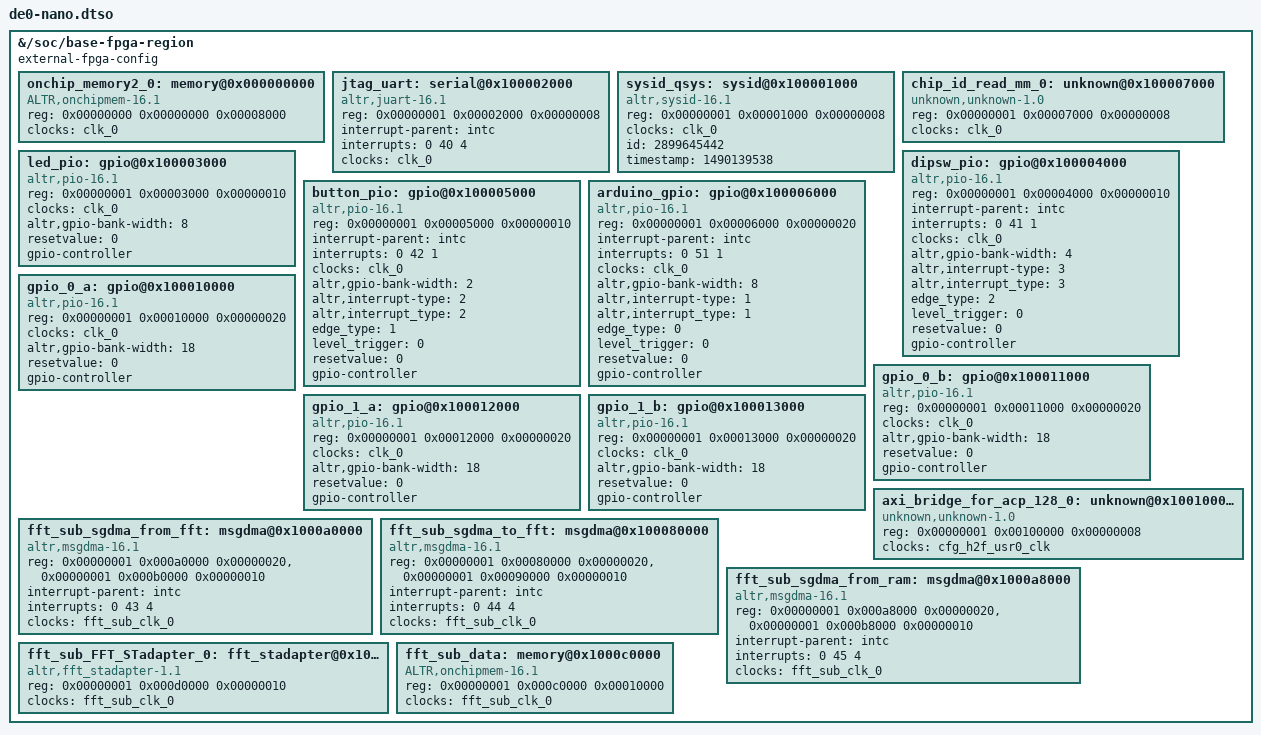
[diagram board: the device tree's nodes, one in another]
/*
 * This devicetree is generated by sopc2dts version  on Tue Mar 21 16:55:32 PDT 2017
 * Sopc2dts is written by Walter Goossens <waltergoossens@home.nl>
 * in cooperation with the nios2 community <nios2-dev@lists.rocketboards.org>
 */
/dts-v1/;
/plugin/;
/include/ "de0-nano.dtsi"

/ {

	fragment@0 {
		target-path = "/soc/base-fpga-region";

		__overlay__ {
			external-fpga-config;
			#address-cells = <2>;
			#size-cells = <1>;
			ranges = <0x00000000 0x00000000 0xc0000000 0x20000000>,
				<0x00000001 0x00000000 0xff200000 0x00200000>;

			onchip_memory2_0: memory@0x000000000 {
				device_type = "memory";
				compatible = "ALTR,onchipmem-16.1";
				reg = <0x00000000 0x00000000 0x00008000>;
				clocks = <&clk_0>;
			}; //end memory@0x000000000 (onchip_memory2_0)

			jtag_uart: serial@0x100002000 {
				compatible = "altr,juart-16.1", "altr,juart-1.0";
				reg = <0x00000001 0x00002000 0x00000008>;
				interrupt-parent = <&intc>;
				interrupts = <0 40 4>;
				clocks = <&clk_0>;
			}; //end serial@0x100002000 (jtag_uart)

			sysid_qsys: sysid@0x100001000 {
				compatible = "altr,sysid-16.1", "altr,sysid-1.0";
				reg = <0x00000001 0x00001000 0x00000008>;
				clocks = <&clk_0>;
				id = <2899645442>;	/* embeddedsw.dts.params.id type NUMBER */
				timestamp = <1490139538>;	/* embeddedsw.dts.params.timestamp type NUMBER */
			}; //end sysid@0x100001000 (sysid_qsys)

			chip_id_read_mm_0: unknown@0x100007000 {
				compatible = "unknown,unknown-1.0";
				reg = <0x00000001 0x00007000 0x00000008>;
				clocks = <&clk_0>;
			}; //end unknown@0x100007000 (chip_id_read_mm_0)

			led_pio: gpio@0x100003000 {
				compatible = "altr,pio-16.1", "altr,pio-1.0";
				reg = <0x00000001 0x00003000 0x00000010>;
				clocks = <&clk_0>;
				altr,gpio-bank-width = <8>;	/* embeddedsw.dts.params.altr,gpio-bank-width type NUMBER */
				resetvalue = <0>;	/* embeddedsw.dts.params.resetvalue type NUMBER */
				#gpio-cells = <2>;
				gpio-controller;
			}; //end gpio@0x100003000 (led_pio)

			dipsw_pio: gpio@0x100004000 {
				compatible = "altr,pio-16.1", "altr,pio-1.0";
				reg = <0x00000001 0x00004000 0x00000010>;
				interrupt-parent = <&intc>;
				interrupts = <0 41 1>;
				clocks = <&clk_0>;
				altr,gpio-bank-width = <4>;	/* embeddedsw.dts.params.altr,gpio-bank-width type NUMBER */
				altr,interrupt-type = <3>;	/* embeddedsw.dts.params.altr,interrupt-type type NUMBER */
				altr,interrupt_type = <3>;	/* embeddedsw.dts.params.altr,interrupt_type type NUMBER */
				edge_type = <2>;	/* embeddedsw.dts.params.edge_type type NUMBER */
				level_trigger = <0>;	/* embeddedsw.dts.params.level_trigger type NUMBER */
				resetvalue = <0>;	/* embeddedsw.dts.params.resetvalue type NUMBER */
				#gpio-cells = <2>;
				gpio-controller;
			}; //end gpio@0x100004000 (dipsw_pio)

			button_pio: gpio@0x100005000 {
				compatible = "altr,pio-16.1", "altr,pio-1.0";
				reg = <0x00000001 0x00005000 0x00000010>;
				interrupt-parent = <&intc>;
				interrupts = <0 42 1>;
				clocks = <&clk_0>;
				altr,gpio-bank-width = <2>;	/* embeddedsw.dts.params.altr,gpio-bank-width type NUMBER */
				altr,interrupt-type = <2>;	/* embeddedsw.dts.params.altr,interrupt-type type NUMBER */
				altr,interrupt_type = <2>;	/* embeddedsw.dts.params.altr,interrupt_type type NUMBER */
				edge_type = <1>;	/* embeddedsw.dts.params.edge_type type NUMBER */
				level_trigger = <0>;	/* embeddedsw.dts.params.level_trigger type NUMBER */
				resetvalue = <0>;	/* embeddedsw.dts.params.resetvalue type NUMBER */
				#gpio-cells = <2>;
				gpio-controller;
			}; //end gpio@0x100005000 (button_pio)

			arduino_gpio: gpio@0x100006000 {
				compatible = "altr,pio-16.1", "altr,pio-1.0";
				reg = <0x00000001 0x00006000 0x00000020>;
				interrupt-parent = <&intc>;
				interrupts = <0 51 1>;
				clocks = <&clk_0>;
				altr,gpio-bank-width = <8>;	/* embeddedsw.dts.params.altr,gpio-bank-width type NUMBER */
				altr,interrupt-type = <1>;	/* embeddedsw.dts.params.altr,interrupt-type type NUMBER */
				altr,interrupt_type = <1>;	/* embeddedsw.dts.params.altr,interrupt_type type NUMBER */
				edge_type = <0>;	/* embeddedsw.dts.params.edge_type type NUMBER */
				level_trigger = <0>;	/* embeddedsw.dts.params.level_trigger type NUMBER */
				resetvalue = <0>;	/* embeddedsw.dts.params.resetvalue type NUMBER */
				#gpio-cells = <2>;
				gpio-controller;
			}; //end gpio@0x100006000 (arduino_gpio)

			gpio_0_a: gpio@0x100010000 {
				compatible = "altr,pio-16.1", "altr,pio-1.0";
				reg = <0x00000001 0x00010000 0x00000020>;
				clocks = <&clk_0>;
				altr,gpio-bank-width = <18>;	/* embeddedsw.dts.params.altr,gpio-bank-width type NUMBER */
				resetvalue = <0>;	/* embeddedsw.dts.params.resetvalue type NUMBER */
				#gpio-cells = <2>;
				gpio-controller;
			}; //end gpio@0x100010000 (gpio_0_a)

			gpio_0_b: gpio@0x100011000 {
				compatible = "altr,pio-16.1", "altr,pio-1.0";
				reg = <0x00000001 0x00011000 0x00000020>;
				clocks = <&clk_0>;
				altr,gpio-bank-width = <18>;	/* embeddedsw.dts.params.altr,gpio-bank-width type NUMBER */
				resetvalue = <0>;	/* embeddedsw.dts.params.resetvalue type NUMBER */
				#gpio-cells = <2>;
				gpio-controller;
			}; //end gpio@0x100011000 (gpio_0_b)

			gpio_1_a: gpio@0x100012000 {
				compatible = "altr,pio-16.1", "altr,pio-1.0";
				reg = <0x00000001 0x00012000 0x00000020>;
				clocks = <&clk_0>;
				altr,gpio-bank-width = <18>;	/* embeddedsw.dts.params.altr,gpio-bank-width type NUMBER */
				resetvalue = <0>;	/* embeddedsw.dts.params.resetvalue type NUMBER */
				#gpio-cells = <2>;
				gpio-controller;
			}; //end gpio@0x100012000 (gpio_1_a)

			gpio_1_b: gpio@0x100013000 {
				compatible = "altr,pio-16.1", "altr,pio-1.0";
				reg = <0x00000001 0x00013000 0x00000020>;
				clocks = <&clk_0>;
				altr,gpio-bank-width = <18>;	/* embeddedsw.dts.params.altr,gpio-bank-width type NUMBER */
				resetvalue = <0>;	/* embeddedsw.dts.params.resetvalue type NUMBER */
				#gpio-cells = <2>;
				gpio-controller;
			}; //end gpio@0x100013000 (gpio_1_b)

			axi_bridge_for_acp_128_0: unknown@0x100100000 {
				compatible = "unknown,unknown-1.0";
				reg = <0x00000001 0x00100000 0x00000008>;
				clocks = <&cfg_h2f_usr0_clk>;
			}; //end unknown@0x100100000 (axi_bridge_for_acp_128_0)

			fft_sub_sgdma_from_fft: msgdma@0x1000a0000 {
				compatible = "altr,msgdma-16.1", "altr,msgdma-1.0";
				reg = <0x00000001 0x000a0000 0x00000020>,
					<0x00000001 0x000b0000 0x00000010>;
				reg-names = "csr", "descriptor_slave";
				interrupt-parent = <&intc>;
				interrupts = <0 43 4>;
				clocks = <&fft_sub_clk_0>;
			}; //end msgdma@0x1000a0000 (fft_sub_sgdma_from_fft)

			fft_sub_sgdma_to_fft: msgdma@0x100080000 {
				compatible = "altr,msgdma-16.1", "altr,msgdma-1.0";
				reg = <0x00000001 0x00080000 0x00000020>,
					<0x00000001 0x00090000 0x00000010>;
				reg-names = "csr", "descriptor_slave";
				interrupt-parent = <&intc>;
				interrupts = <0 44 4>;
				clocks = <&fft_sub_clk_0>;
			}; //end msgdma@0x100080000 (fft_sub_sgdma_to_fft)

			fft_sub_sgdma_from_ram: msgdma@0x1000a8000 {
				compatible = "altr,msgdma-16.1", "altr,msgdma-1.0";
				reg = <0x00000001 0x000a8000 0x00000020>,
					<0x00000001 0x000b8000 0x00000010>;
				reg-names = "csr", "descriptor_slave";
				interrupt-parent = <&intc>;
				interrupts = <0 45 4>;
				clocks = <&fft_sub_clk_0>;
			}; //end msgdma@0x1000a8000 (fft_sub_sgdma_from_ram)

			fft_sub_FFT_STadapter_0: fft_stadapter@0x1000d0000 {
				compatible = "altr,fft_stadapter-1.1", "altr,fft_stadapter";
				reg = <0x00000001 0x000d0000 0x00000010>;
				clocks = <&fft_sub_clk_0>;
			}; //end fft_stadapter@0x1000d0000 (fft_sub_FFT_STadapter_0)

			fft_sub_data: memory@0x1000c0000 {
				device_type = "memory";
				compatible = "ALTR,onchipmem-16.1";
				reg = <0x00000001 0x000c0000 0x00010000>;
				clocks = <&fft_sub_clk_0>;
			}; //end memory@0x1000c0000 (fft_sub_data)
		}; //end __overlay__
	}; //end fragment@0
}; //end /
